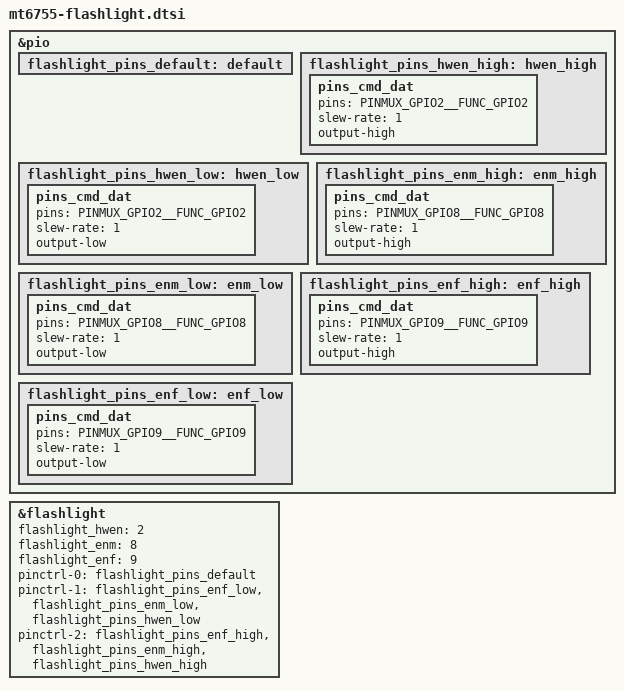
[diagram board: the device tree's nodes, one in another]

/*modif flashight gpio code*/
/* FLASHLIGHT GPIO standardization */
&pio {
	flashlight_pins_default: default {

	};
	flashlight_pins_hwen_high: hwen_high {

	    pins_cmd_dat {
			pins = <PINMUX_GPIO2__FUNC_GPIO2>;
			slew-rate = <1>;
			output-high;
		};
	};

	flashlight_pins_hwen_low: hwen_low {

	    pins_cmd_dat {
			pins = <PINMUX_GPIO2__FUNC_GPIO2>;
			slew-rate = <1>;
			output-low;
		};
	};
	flashlight_pins_enm_high: enm_high {
	    pins_cmd_dat {
			pins = <PINMUX_GPIO8__FUNC_GPIO8>;
			slew-rate = <1>;
			output-high;
		};
	};
	flashlight_pins_enm_low: enm_low {
	    pins_cmd_dat {
			pins = <PINMUX_GPIO8__FUNC_GPIO8>;
			slew-rate = <1>;
			output-low;
		};
	};
	flashlight_pins_enf_high: enf_high {
	    pins_cmd_dat {
			pins = <PINMUX_GPIO9__FUNC_GPIO9>;
			slew-rate = <1>;
			output-high;
		};
	};
	flashlight_pins_enf_low: enf_low {
	    pins_cmd_dat {
			pins = <PINMUX_GPIO9__FUNC_GPIO9>;
			slew-rate = <1>;
			output-low;
		};
	};
};

&flashlight {
	flashlight_hwen = <2>;
	flashlight_enm = <8>;
	flashlight_enf = <9>;
	pinctrl-names = "default", "init_all_low", "init_all_high";
	pinctrl-0 = <&flashlight_pins_default>;
	pinctrl-1 = <&flashlight_pins_enf_low  &flashlight_pins_enm_low  &flashlight_pins_hwen_low>;
	pinctrl-2 = <&flashlight_pins_enf_high &flashlight_pins_enm_high &flashlight_pins_hwen_high>;
	status = "okay";

};
/* FLASHLIGHT GPIO end */

